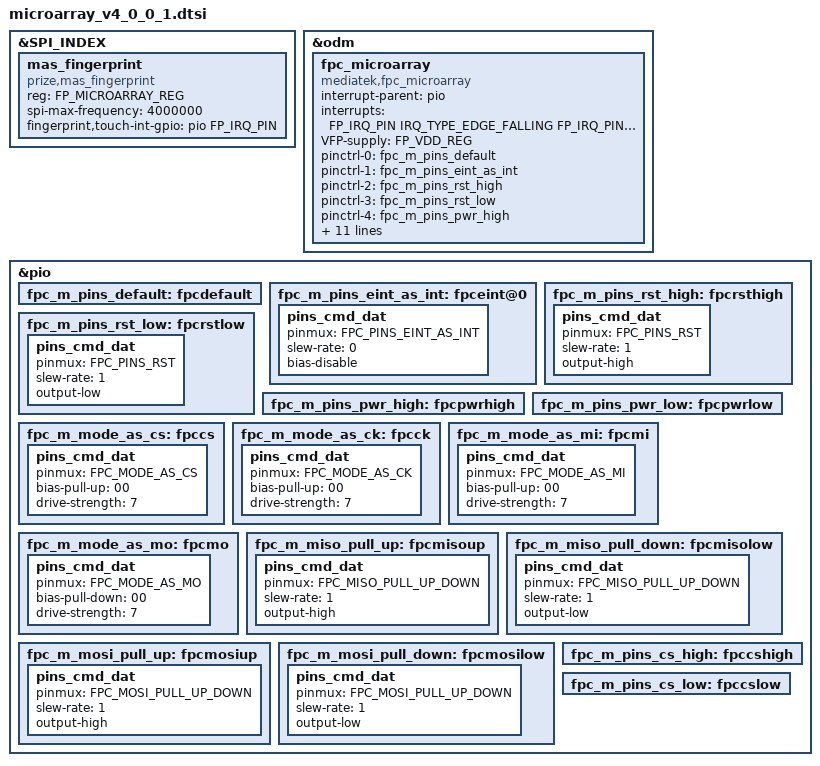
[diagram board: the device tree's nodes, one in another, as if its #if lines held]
#include "../../drv_common.h"

#if PRI_PLATFORM_MT6789
#include "./mt6789/custom.h"
#endif

#if PRI_PLATFORM_MT6835
#include "./mt6835/custom.h"
#endif


/*******************************************************************************
 * fingerprint
 *******************************************************************************/
 /* Fingerprint GPIO standardization */
&SPI_INDEX{
	#address-cells = <1>;
	#size-cells = <0>;
	mas_fingerprint: mas_fingerprint{
		compatible = "prize,mas_fingerprint";
		reg = <FP_MICROARRAY_REG>;
		spi-max-frequency = <4000000>;
		/*other infromation*/
		/*spi-cpha;*/    /*set cpha=1, optional*/
		/*spi-cpol;*/    /*set cpol=1, optional*/
		/*spi-cs-high;*/    /*set cs active level=1, optional*/
		/*spi-3wire;*/    /*set no-tx or no-rx, optional*/
		/*spi-lsb-first;*/    /*set lsb-first transfer, optional*/
		fingerprint,touch-int-gpio = <&pio FP_IRQ_PIN 0>;
		status = "okay";
	};

};

&odm{
	fpc_microarray:fpc_microarray{
		compatible = "mediatek,fpc_microarray";
 		interrupt-parent = <&pio>;
 		interrupts = <FP_IRQ_PIN IRQ_TYPE_EDGE_FALLING FP_IRQ_PIN 0>;
 		VFP-supply = <&FP_VDD_REG>;
 		pinctrl-names = "default",
 			"fpc_eint_as_int",
 			"fpc_pins_rst_high", "fpc_pins_rst_low",
			"fpc_pins_pwr_high", "fpc_pins_pwr_low",
 			"fpc_mode_as_cs",    "fpc_mode_as_ck",	
			"fpc_mode_as_mi",    "fpc_mode_as_mo",
 			"fpc_miso_pull_up",  "fpc_miso_pull_down",
			"fpc_mosi_pull_up",  "fpc_mosi_pull_down",
 			"fpc_pins_cs_high",  "fpc_pins_cs_low";
 		pinctrl-0 =  <&fpc_m_pins_default>;
 		pinctrl-1 =  <&fpc_m_pins_eint_as_int>;
 		pinctrl-2 =  <&fpc_m_pins_rst_high>;
 		pinctrl-3 =  <&fpc_m_pins_rst_low>;
 		pinctrl-4 =  <&fpc_m_pins_pwr_high>;
 		pinctrl-5 =  <&fpc_m_pins_pwr_low>;
 		pinctrl-6 =  <&fpc_m_mode_as_cs>;
 		pinctrl-7 =  <&fpc_m_mode_as_ck>;
 		pinctrl-8=   <&fpc_m_mode_as_mi>;
 		pinctrl-9 =  <&fpc_m_mode_as_mo>;
 		pinctrl-10 = <&fpc_m_miso_pull_up>;
 		pinctrl-11 = <&fpc_m_miso_pull_down>;
 		pinctrl-12 = <&fpc_m_mosi_pull_up>;
 		pinctrl-13 = <&fpc_m_mosi_pull_down>;
 		pinctrl-14 = <&fpc_m_pins_cs_high>;
 		pinctrl-15 = <&fpc_m_pins_cs_low>;
 		status = "okay";
	};
};

&pio {
	fpc_m_pins_default: fpcdefault {
	};

	fpc_m_pins_eint_as_int: fpceint@0{
		pins_cmd_dat {
			pinmux = <FPC_PINS_EINT_AS_INT>;
			slew-rate = <0>;
			bias-disable;
		};
	};
	fpc_m_pins_rst_high: fpcrsthigh {
		pins_cmd_dat {
			pinmux = <FPC_PINS_RST>;
			slew-rate = <1>;
			output-high;
		};
	};
	fpc_m_pins_rst_low: fpcrstlow {
		pins_cmd_dat {
			pinmux = <FPC_PINS_RST>;
			slew-rate = <1>;
			output-low;
		};
	};
	fpc_m_pins_pwr_high: fpcpwrhigh {
	};
	fpc_m_pins_pwr_low: fpcpwrlow {
	};	
	fpc_m_mode_as_cs: fpccs {
		pins_cmd_dat {
			pinmux = <FPC_MODE_AS_CS>;
			bias-pull-up = <00>;
			drive-strength = <7>; 
		};
	};
	fpc_m_mode_as_ck: fpcck {
		pins_cmd_dat {
			pinmux = <FPC_MODE_AS_CK>;
			bias-pull-up = <00>;
			drive-strength = <7>; 
		};
	};
	fpc_m_mode_as_mi: fpcmi {
		pins_cmd_dat {
			pinmux = <FPC_MODE_AS_MI>;
			bias-pull-up = <00>;
			drive-strength = <7>; 
		};
	};
	fpc_m_mode_as_mo: fpcmo {
		pins_cmd_dat {
			pinmux = <FPC_MODE_AS_MO>;
			bias-pull-down = <00>;
			drive-strength = <7>; 
		};
	};
	fpc_m_miso_pull_up: fpcmisoup {
		pins_cmd_dat {
			pinmux = <FPC_MISO_PULL_UP_DOWN>;
			slew-rate = <1>;
			output-high;
		};
	};
	fpc_m_miso_pull_down: fpcmisolow {
		pins_cmd_dat {
			pinmux = <FPC_MISO_PULL_UP_DOWN>;
			slew-rate = <1>;
			output-low;
		};
	};
	fpc_m_mosi_pull_up: fpcmosiup {
		pins_cmd_dat {
			pinmux = <FPC_MOSI_PULL_UP_DOWN>;
			slew-rate = <1>;
			output-high;
		};
	};
	fpc_m_mosi_pull_down: fpcmosilow {
		pins_cmd_dat {
			pinmux = <FPC_MOSI_PULL_UP_DOWN>;
 			slew-rate = <1>;
 			output-low;
 		};
 	};
 	fpc_m_pins_cs_high: fpccshigh {//chipone
 	};
 	fpc_m_pins_cs_low: fpccslow {//chipone
 	};
};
